# apollo4p register map
Vendor: Ambiq Micro; Series: Apollo; File version: 1.0
CPU: CM4 r1p0, little endian, MPU, FPU, I-cache, D-cache, VTOR, ITCM, DTCM, 3 interrupt priority bits, 0 interrupts
Registers are 32-bit, read-write, reset 0x0 unless marked. A register's access mark holds for its fields unless they carry their own. Offsets are from the block's base; [hi:lo] are bit positions; {n}, {i} and the like mark numbered series; 'fields as' and 'values as' point back to an identical list.

## MCUCTRL — MCU Miscellaneous Control Logic
Base 0x40020000
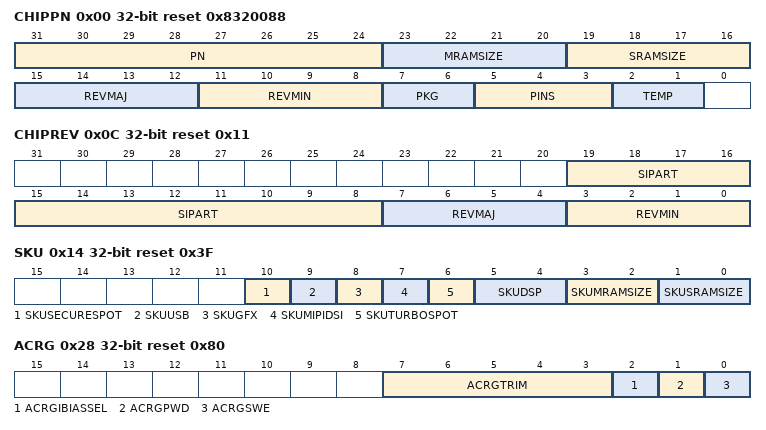
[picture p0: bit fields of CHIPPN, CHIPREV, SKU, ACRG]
0x00 CHIPPN reset 0x8320088 — Chip Information
  [31:24] PN — Apollo family device type.
    9=APOLLO4L (Apollo4L part number is 0x09xxxxxx.); 8=APOLLO4 (Apollo4 part number is 0x08xxxxxx.); 7=APOLLO3P (Apollo3P part number is 0x07xxxxxx.); 6=APOLLO3 (Apollo3 part number is 0x06xxxxxx.); 3=APOLLO2 (Apollo2 part number is 0x03xxxxxx.); 1=APOLLO (Apollo part number is 0x01xxxxxx.)
  [23:20] MRAMSIZE
    0=0P5MB (MRAM size is 0.5MB); 1=1P0MB (MRAM size is 1.0MB); 2=1P5MB (MRAM size is 1.5MB); 3=2P0MB (MRAM size is 2.0MB)
  [19:16] SRAMSIZE
    0=384_512 (SRAM size is 384KB+512KB); 1=384_1024 (SRAM size is 384KB+1MB); 2=384_1024_384_96 (SRAM size is 384KB+1MB+384KB+96KB)
  [15:12] REVMAJ — Major revision.
    0=A (Major Rev A); 1=B (Major Rev B); 2=C (Major Rev C)
  [11:8] REVMIN — Minor revision.
    0=Minor Rev 0; 1=Minor Rev 1
  [7:6] PKG — Package type.
    0=SIP (SIP package.); 1=SIP2 (SIP2 package.); 2=BGA (BGA package.); 3=CSP (CSP package.)
  [5:3] PINS — Number of pins for this package.
    0=25 pins; 1=49 pins; 2=64 pins; 3=81 pins
  [2:1] TEMP — Temperature.
    0=COM (Commercial temperature); 1=MIL (Military temperature); 2=AUTO (Automotive temperature); 3=IND (Industrial temperature)
0x04 CHIPID0 — Unique Chip ID 0
  [31:0] CHIPID0 — Unique chip ID 0.
0x08 CHIPID1 — Unique Chip ID 1
  [31:0] CHIPID1 — Unique chip ID 1.
0x0C CHIPREV reset 0x11 — Chip Revision
  [19:8] SIPART — Silicon Part ID
  [7:4] REVMAJ — Major Revision ID.
    3=C (Apollo4 revision C); 2=B (Apollo4 revision B); 1=A (Apollo4 revision A)
  [3:0] REVMIN — Minor Revision ID.
    3=REV2 (Apollo4 minor rev 2.); 2=REV1 (Apollo4 minor rev 1.); 1=REV0 (Apollo4 minor rev 0. Minor revision value, succeeding minor revisions will increment from this value.)
0x10 VENDORID — Unique Vendor ID
  [31:0] VENDORID
    0x414D4251=AMBIQ (Ambiq Vendor ID 'AMBQ'); 0=DEFAULT (Default Vendor ID)
0x14 SKU reset 0x3F — Unique Chip SKU
  [10] SKUSECURESPOT — Secure boot feature
  [9] SKUUSB — USB available
  [8] SKUGFX — GFX available
  [7] SKUMIPIDSI — MIPI DSI available
  [6] SKUTURBOSPOT — High performance mode for MCU and DSPs.
  [5:4] SKUDSP — DSP availability SKU setting. 384K available by default. Memory SU disabled
  [3:2] SKUMRAMSIZE — MRAM size SKU. All of 2MB Available by default. Memory SU disabled
  [1:0] SKUSRAMSIZE — SRAM SKU dictates the available memory for MCU. All of the MCU TCM (384KB) and System SRAM (2MB) available by default. Memory SU disabled
0x20 DEBUGGER — Debugger Control
  [31:0] LOCKOUT — Lockout of debugger (SWD).
0x28 ACRG reset 0x80 — Active Current Reference Generator Control
  [7:3] ACRGTRIM — ACRG Trim value
  [2] ACRGIBIASSEL — Set the ACRG ibias. Note: the SWE mux select in PWRSEQ2SWE must be set for this to take effect. The inversion of this register is driven to analog.
    0=BGSEL (Selects the bandgap); 1=CCRGSEL (Selects the CCRG)
  [1] ACRGPWD — Power down the ACRG.
    1=ACRG_PWR_DN (Powers down the ACRG trim.); 0=ACRG_PWR_UP (Power up the ACRG trim.)
  [0] ACRGSWE — Software enablement for ACRG register. A value of 1 will allow writes to the register
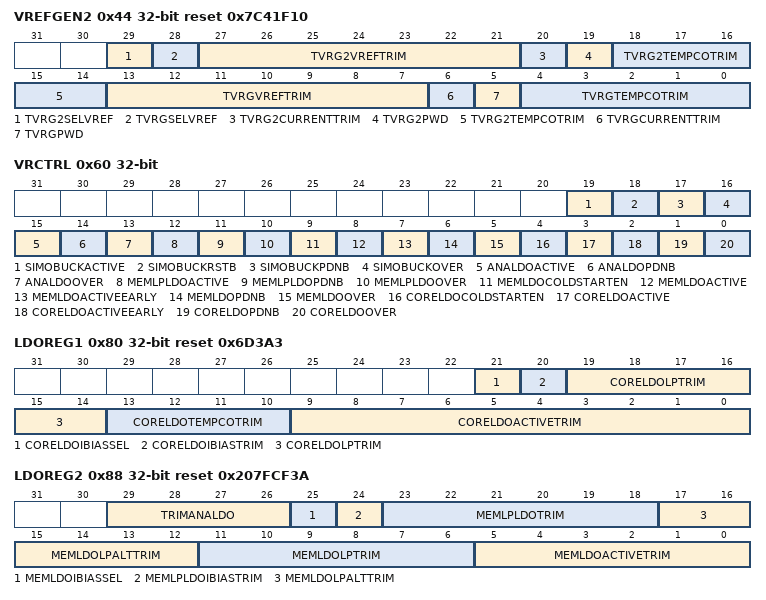
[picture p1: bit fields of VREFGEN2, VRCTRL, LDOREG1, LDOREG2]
0x44 VREFGEN2 reset 0x7C41F10 — Voltage Reference Generator 2 Control
  [29] TVRG2SELVREF
  [28] TVRGSELVREF
  [27:21] TVRG2VREFTRIM — Calibrated voltage reference 580m trim
  [20] TVRG2CURRENTTRIM — Calibrated voltage reference current trim.
  [19] TVRG2PWD — Power Down, Calibrated Voltage Reference Generator.
    1=PWR_DN (Powers down the CVRG.); 0=PWR_UP (Power up the CVRG.)
  [18:14] TVRG2TEMPCOTRIM — Calibrated Voltage Reference Generator tc trim (bottom transistor)
  [13:7] TVRGVREFTRIM — Calibrated voltage reference 580m trim
  [6] TVRGCURRENTTRIM — Calibrated voltage reference current trim.
  [5] TVRGPWD — Power Down, Calibrated Voltage Reference Generator.
    values as TVRG2PWD
  [4:0] TVRGTEMPCOTRIM — Calibrated Voltage Reference Generator tc trim (bottom transistor)
0x60 VRCTRL — Overrides for Voltage Regulators Controls
  [19] SIMOBUCKACTIVE — SIMO BUCK ACTIVE control. Override for PWRCTRL going to analog when SIMOBUCKOVER = 1
  [18] SIMOBUCKRSTB — SIMO BUCK RSTB control. Override for PWRCTRL going to analog when SIMOBUCKOVER = 1
  [17] SIMOBUCKPDNB — SIMO BUCK PDNB control. Override for PWRCTRL going to analog when SIMOBUCKOVER = 1
  [16] SIMOBUCKOVER — Override control for SIMO BUCK signals
  [15] ANALDOACTIVE — ANALDO LDO ACTIVE control. Override for PWRCTRL going to analog when ANALDOOVER = 1
  [14] ANALDOPDNB — ANALDO PDNB control. Override for PWRCTRL going to analog when ANALDOOVER = 1
  [13] ANALDOOVER — Override control for ANALDO signals
  [12] MEMLPLDOACTIVE — MEM LP LDO ACTVIVE control. Override for PWRCTRL going to analog when MEMLPLDOOVER = 1
  [11] MEMLPLDOPDNB — MEM LP LDO PDNB control. Override for PWRCTRL going to analog when MEMLPLDOOVER = 1
  [10] MEMLPLDOOVER — Override control for MEM LP LDO signals
  [9] MEMLDOCOLDSTARTEN — MEM LDO COLDSTART EN control. This is a shadow backed register and no need to set MEMLDOOVER.
  [8] MEMLDOACTIVE — MEM LDO ACTIVE control. Override for PWRCTRL going to analog when MEMLDOOVER = 1
  [7] MEMLDOACTIVEEARLY — MEM LDO EARLY ACTIVE control. Override for PWRCTRL going to analog when MEMLDOOVER = 1
  [6] MEMLDOPDNB — MEM LDO PDNB control. Override signal for PWRCTRL going to analog when MEMLDOOVER = 1
  [5] MEMLDOOVER — Override control for MEM LDO signals
  [4] CORELDOCOLDSTARTEN — CORE LDO COLDSTART EN control. This is a shadow backed register and no need to set CORELDOOVER.
  [3] CORELDOACTIVE — CORE LDO ACTIVE control. Override for PWRCTRL going to analog when CORELDOOVER = 1
  [2] CORELDOACTIVEEARLY — CORE LDO EARLY ACTIVE control. Override for PWRCTRL going to analog when CORELDOOVER = 1
  [1] CORELDOPDNB — CORE LDO PDNB control. Override for PWRCTRL going to analog when CORELDOOVER = 1
  [0] CORELDOOVER — Override control for CORE LDO signals
0x80 LDOREG1 reset 0x6D3A3 — CORELDO trims Reg
  [21] CORELDOIBIASSEL — Core LDO IBIAS sel. Note: the SWE mux select in PWRSEQ2SWE must be set for this to take effect.
  [20] CORELDOIBIASTRIM
  [19:14] CORELDOLPTRIM — CORE LDO Low Power Trim
  [13:10] CORELDOTEMPCOTRIM
  [9:0] CORELDOACTIVETRIM
0x88 LDOREG2 reset 0x207FCF3A — MEMLDO and MEMLPLDO Trims
  [29:26] TRIMANALDO — Analog LDO Trim.
  [25] MEMLDOIBIASSEL — Mem LDO IBIAS sel. Note: the SWE mux select in PWRSEQ2SWE must be set for this to take effect.
  [24] MEMLPLDOIBIASTRIM
  [23:18] MEMLPLDOTRIM
  [17:12] MEMLDOLPALTTRIM — MEM LDO TRIM LP ALT SET
  [11:6] MEMLDOLPTRIM
  [5:0] MEMLDOACTIVETRIM
0xC4 HFRC2 — HFRC2 Control
  [21:11] HF2TUNE — Default HFRC2 frequency tune value
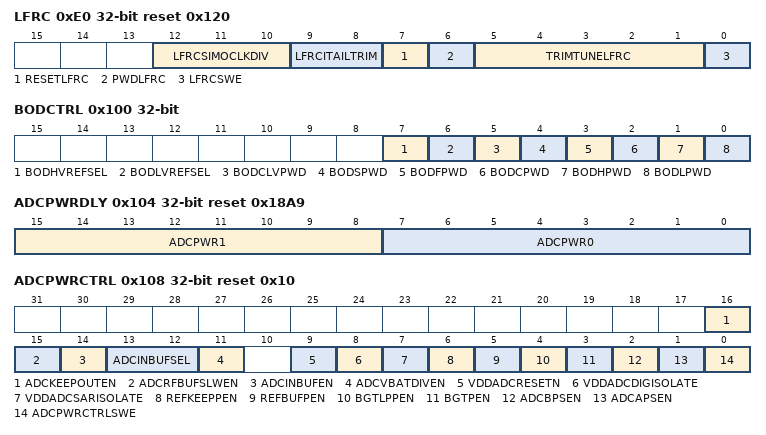
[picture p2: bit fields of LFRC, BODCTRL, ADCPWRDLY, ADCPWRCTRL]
0xE0 LFRC reset 0x120 — LFRC Control
  [12:10] LFRCSIMOCLKDIV — SIMOBUCK LP mode clock divider
    0=DIV1 (Divide by 1); 1=DIV2 (Divide by 2); 2=DIV4 (Divide by 4); 3=DIV8 (Divide by 8); 4=DIV16 (Divide by 16); 5=DIV32 (Divide by 32)
  [9:8] LFRCITAILTRIM
  [7] RESETLFRC — LFRC Reset.
    0=EN (Enable LFRC.); 1=RESET (Reset LFRC.)
  [6] PWDLFRC — Power Down LFRC.
    0=PWRUP (Power up LFRC.); 1=PWRDN (Power down LFRC.)
  [5:1] TRIMTUNELFRC — LFRC Frequency Tune trim bits
  [0] LFRCSWE — LFRC Software Override Enable.
    0=OVERRIDE_DIS (LFRC Software Override Disable.); 1=OVERRIDE_EN (LFRC Software Override Enable.)
0x100 BODCTRL — BOD control
  [7] BODHVREFSEL — BODH External Reference Select. Note: the SWE mux select in PWRSEQ2SWE must be set for this to take effect.
  [6] BODLVREFSEL — BODL External Reference Select. Note: the SWE mux select in PWRSEQ2SWE must be set for this to take effect.
  [5] BODCLVPWD — BODC_LV Power Down.
  [4] BODSPWD — BODS Power Down.
  [3] BODFPWD — BODF Power Down.
  [2] BODCPWD — BODC Power Down.
  [1] BODHPWD — BODH Power Down.
  [0] BODLPWD — BODL Power Down.
0x104 ADCPWRDLY reset 0x18A9 — ADC Power Up Delay Control
  [15:8] ADCPWR1 — Delay time for ADC Reference Buffer settling time in 64x ADC clock increments. Delay = 64*ADCPWR1*ADC_CLK
  [7:0] ADCPWR0 — Additional delay time for ADC Reference Buffer settling time in 64x ADC clock increments. Delay = 64*ADCPWR0*ADC_CLK.
0x108 ADCPWRCTRL reset 0x10 — ADC Power Control
  [16] ADCKEEPOUTEN — ADC reference keeper out en
  [15] ADCRFBUFSLWEN — ADC reference buffer slew enable
  [14] ADCINBUFEN — ADC Input Buffer Power Enable ( if the ADCPWRCTRLSWE bit is set )
  [13:12] ADCINBUFSEL — ADC input buffer mux select
  [11] ADCVBATDIVEN — ADC VBAT DIV Power Enable ( if the ADCPWRCTRLSWE bit is set )
  [9] VDDADCRESETN — RESETN signal for Power Switched SAR and Digital Controller (when global power switch is off and if the ADCPWRCTRLSWE bit is set)
    0=ASSERT (Resetn is asserted); 1=DEASSERT (Resetn is de-asserted)
  [8] VDDADCDIGISOLATE — ISOLATE signal for ADC Digital Contoller ( when ADCAPSEN is switched off and if the ADCPWRCTRLSWE bit is set)
    0=DIS (No Isolation); 1=EN (Isolate)
  [7] VDDADCSARISOLATE — ISOLATE signal for Power Switched SAR ( when ADCBPSEN is switched off )
    0=DIS (No Isolation); 1=EN (Isolate)
  [6] REFKEEPPEN — Reference Buffer Keeper Power Switch Enable
    0=DIS (Reference Buffer Keeper Power Switch disable.); 1=EN (Reference Buffer Keeper Power Switch enable.)
  [5] REFBUFPEN — Reference Buffer Power Switch Enable
    0=DIS (Reference Buffer Power Switch disable.); 1=EN (Reference Buffer Power Switch enable.)
  [4] BGTLPPEN — Bandgap and Temperature Sensor Power Switch Enable
    0=DIS (Bandgap and temperature sensor disable.); 1=EN (Bandgap and temperature sensor enable.)
  [3] BGTPEN — Bandgap and Temperature Sensor Power Switch Enable
    values as BGTLPPEN
  [2] ADCBPSEN — Enable the Analog, IO and SAR Digital logic Power Switch on when set to 1 if the ADCPWRCTRLSWE bit is set.
    0=DIS (ADC power switch software power disable.); 1=EN (ADC power switch software power enable.)
  [1] ADCAPSEN — Enable the Global ADC Power Switch on when set to 1 if the ADCPWRCTRLSWE bit is set.
    values as ADCBPSEN
  [0] ADCPWRCTRLSWE — ADC Power Control Software Override Enable
    0=OVERRIDE_DIS (ADC temperature sensor and bandgap Software Override Disable.); 1=OVERRIDE_EN (ADC temperature sensor and bandgap Software Override Enable.)
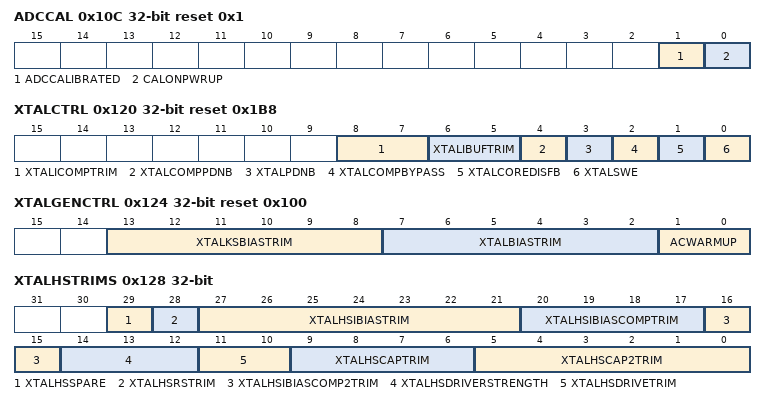
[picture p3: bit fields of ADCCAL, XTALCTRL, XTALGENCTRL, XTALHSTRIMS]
0x10C ADCCAL reset 0x1 — ADC Calibration Control
  [1] ADCCALIBRATED — Status for ADC Calibration
    0=FALSE (ADC is not calibrated); 1=TRUE (ADC is calibrated)
  [0] CALONPWRUP — Run ADC Calibration on initial power up sequence
    0=DIS (Disable automatic calibration on initial power up); 1=EN (Enable automatic calibration on initial power up)
0x110 ADCBATTLOAD — ADC Battery Load Enable
  [0] BATTLOAD — Enable the ADC battery load resistor
    0=DIS (Battery load is disconnected); 1=EN (Battery load is enabled)
0x120 XTALCTRL reset 0x1B8 — XTAL Oscillator Control
  [8:7] XTALICOMPTRIM
  [6:5] XTALIBUFTRIM — XTAL IBUFF trim
  [4] XTALCOMPPDNB — XTAL Oscillator Power Down Comparator.
    1=PWRUPCOMP (Power up XTAL oscillator comparator.); 0=PWRDNCOMP (Power down XTAL oscillator comparator.)
  [3] XTALPDNB — XTAL Oscillator Power Down Core.
    1=PWRUPCORE (Power up XTAL oscillator core.); 0=PWRDNCORE (Power down XTAL oscillator core.)
  [2] XTALCOMPBYPASS — XTAL Oscillator Bypass Comparator.
    0=USECOMP (Use the XTAL oscillator comparator.); 1=BYPCOMP (Bypass the XTAL oscillator comparator.)
  [1] XTALCOREDISFB — XTAL Oscillator Disable Feedback.
    0=EN (Enable XTAL oscillator comparator.); 1=DIS (Disable XTAL oscillator comparator.)
  [0] XTALSWE — XTAL Software Override Enable.
    0=OVERRIDE_DIS (XTAL Software Override Disable.); 1=OVERRIDE_EN (XTAL Software Override Enable.)
0x124 XTALGENCTRL reset 0x100 — XTAL Oscillator General Control
  [13:8] XTALKSBIASTRIM — XTAL IBIAS Kick start trim. This trim value is used during the startup process to enable a faster lock.
  [7:2] XTALBIASTRIM
  [1:0] ACWARMUP — Auto-calibration delay control
    0=SEC1 (Warmup period of 1-2 seconds); 1=SEC2 (Warmup period of 2-4 seconds); 2=SEC4 (Warmup period of 4-8 seconds); 3=SEC8 (Warmup period of 8-16 seconds)
0x128 XTALHSTRIMS
  [29] XTALHSSPARE, [28] XTALHSRSTRIM, [27:21] XTALHSIBIASTRIM, [20:17] XTALHSIBIASCOMPTRIM, [16:15] XTALHSIBIASCOMP2TRIM, [14:12] XTALHSDRIVERSTRENGTH, [11:10] XTALHSDRIVETRIM, [9:6] XTALHSCAPTRIM, [5:0] XTALHSCAP2TRIM
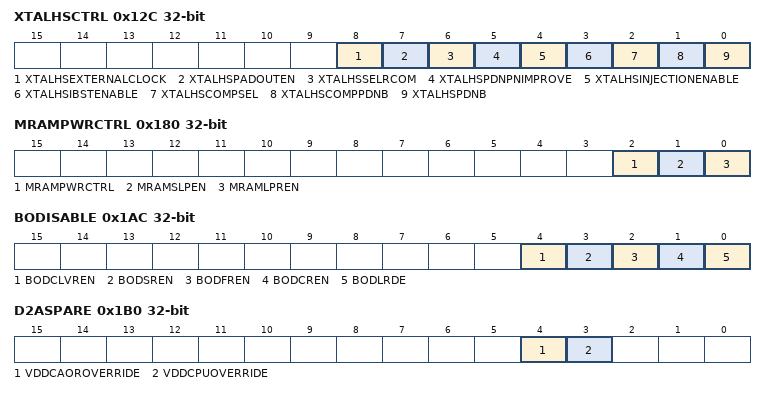
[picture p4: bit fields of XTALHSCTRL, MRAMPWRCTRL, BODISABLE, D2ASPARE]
0x12C XTALHSCTRL — XTALHS Control
  [8] XTALHSEXTERNALCLOCK, [7] XTALHSPADOUTEN, [6] XTALHSSELRCOM, [5] XTALHSPDNPNIMPROVE, [4] XTALHSINJECTIONENABLE, [3] XTALHSIBSTENABLE, [2] XTALHSCOMPSEL, [1] XTALHSCOMPPDNB, [0] XTALHSPDNB
0x180 MRAMPWRCTRL — MRAM Power Control
  [2] MRAMPWRCTRL — MRAM low power mode control. When set to 1, tmc_lpr and tmc_slp are driven by the value of MRAMLPREN and MRAMSLPEN of this register.
  [1] MRAMSLPEN — MRAM sleep mode enable
  [0] MRAMLPREN — MRAM low power mode enable
0x1AC BODISABLE — Brownout Disable
  [4] BODCLVREN — Disable VDDC_LV Brown Out reset.
    1=EN (Enable VDDC_LV Brown Out reset.); 0=DIS (Disable VDDC_LV Brown Out reset.)
  [3] BODSREN — Disable VDDS Brown Out reset.
    1=EN (Enable VDDS Brown Out reset.); 0=DIS (Disable VDDS Brown Out reset.)
  [2] BODFREN — Disable VDDF Brown Out reset.
    1=EN (Enable VDDF Brown Out reset.); 0=DIS (Disable VDDF Brown Out reset.)
  [1] BODCREN — Disable VDDC Brown Out reset.
    1=EN (Enable VDDC Brown Out reset.); 0=DIS (Disable VDDC Brown Out reset.)
  [0] BODLRDE — Disable Unregulated 1.8V Brown-out reset.
    0=EN (Enable Unregulated 1.8v brown out reset.); 1=DIS (Disable Unregulated 1.8v brown out reset.)
0x1B0 D2ASPARE — Spare registers to analog module
  [4] VDDCAOROVERRIDE — VDDCAOR Override. Set to 1 to connect to the VDDC rail, set to 0 to connect to the VDDC_LV rail. Before setting this bit to 0, the VDDC_LV rail must first be enabled by setting SIMOBUCK0_b.VDDCLVRXCOMPEN. Do not modify this field unless directed to do so by Ambiq engineering. If modifying, a RMW operation such as MCUCTRL->D2ASPARE_b.VDDCAOROVERRIDE=1 must be used.
  [3] VDDCPUOVERRIDE — VDDCPU Override. Set to 1 to connect to the VDDC rail, set to 0 to connect to the VDDC_LV rail. Before setting this bit to 0, the VDDC_LV rail must first be enabled by setting SIMOBUCK0_b.VDDCLVRXCOMPEN. Do not modify this field unless directed to do so by Ambiq engineering. If modifying, a RMW operation such as MCUCTRL->D2ASPARE_b.VDDCPUOVERRIDE=1 must be used.
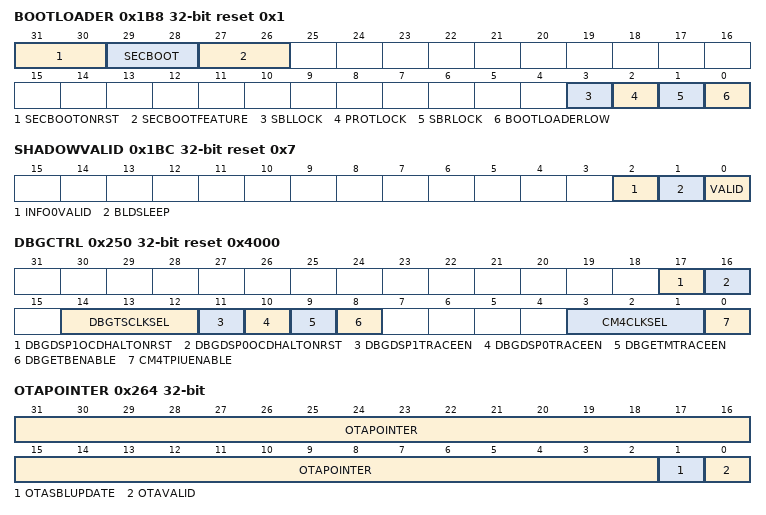
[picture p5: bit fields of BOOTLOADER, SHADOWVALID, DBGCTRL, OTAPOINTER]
0x1B8 BOOTLOADER reset 0x1 — Bootloader and secure boot functions
  [31:30] SECBOOTONRST — Indicates whether the secure boot on warm reset is enabled
    0=DISABLED (Secure boot disabled); 1=ENABLED (Secure boot enabled); 2=ERROR (Error in secure boot configuration)
  [29:28] SECBOOT — Indicates whether the secure boot on cold reset is enabled
    values as SECBOOTONRST
  [27:26] SECBOOTFEATURE — Indicates whether the secure boot feature is enabled.
    values as SECBOOTONRST
  [3] SBLLOCK — Secure boot loader lock. Always resets to 1, write 1 to clear. Enables system visibility to bootloader until set.
    1=LOCK (Enable the secure boot lock); 0=UNLOCK (Disable the secure boot lock)
  [2] PROTLOCK — This field controls access to OEM keybank and restricts further application of NVM protections via the FLASHWPROTn and FLASHRPROTn registers. On read, 0 indicates locked, 1 indicates unlocked. Write 1 to clear the field (assert the lock). Default value of the hardware is 1 (unlocked), but the default value is also affected by INFOC_SECURITY->PLONEXIT. If PLONEXIT is set, PROTLOCK is asserted by SBL and the OEM application will see the value as 0 (locked).
    1=LOCK (On write, this value asserts the lock. On read, see above description.); 0=DEFAULT (On write, this value (writing 0) has no effect. On read, see above description.)
  [1] SBRLOCK — Secure boot ROM lock. Always resets to 1, write 1 to clear. Enables system visibility to bootloader until set.
    1=LOCK (Enable the secure boot lock); 0=DEFAULT (Default value.)
  [0] BOOTLOADERLOW — Determines whether the bootloader code is visible at address 0x00000000 or not. Resets to 1, write 1 to clear.
    1=ADDR0 (Bootloader code at 0x00000000.); 0=NOADDR0 (Bootloader code is not visible at address)
0x1BC SHADOWVALID reset 0x7 — Register to indicate whether the shadow registers have been successfully loaded from the Flash Information Space.
  [2] INFO0VALID — Indicates whether info0 contains valid data
    1=VALID (Flash info0 (customer) space contains valid data.); 0=DEFAULT (Default value.)
  [1] BLDSLEEP — Indicates whether the bootloader should sleep or deep sleep if no image loaded.
    1=DEEPSLEEP (Bootloader will go to deep sleep if no flash image loaded); 0=SLEEP (Bootloader will go to normalsleep if no flash image loaded)
  [0] VALID — Indicates whether the shadow registers contain valid data from the Flash Information Space.
    1=VALID (Flash information space contains valid data.); 0=DEFAULT (Default value.)
0x1C0 SCRATCH0 — Scratch register that is not reset by any reset
  [31:0] SCRATCH0 — Scratch register 0.
0x1C4 SCRATCH1 — Scratch register that is not reset by any reset
  [31:0] SCRATCH1 — Scratch register 1.
0x200 DBGR1 reset 0x12345678 — Read-only debug 1
  [31:0] ONETO8 — Read-only register for communication validation
0x204 DBGR2 reset 0xC001C0DE — Read-only debug 2
  [31:0] COOLCODE — Read-only register for communication validation
0x220 PMUENABLE reset 0x1 — Control bit to enable/disable the PMU
  [0] ENABLE — PMU Enable Control bit. When set, the MCU's PMU will place the MCU into the lowest power consuming Deep Sleep mode upon execution of a WFI instruction (dependent on the setting of the SLEEPDEEP bit in the ARM SCR register). When cleared, regardless of the requested sleep mode, the PMU will not enter the lowest power Deep Sleep mode, instead entering the Sleep mode.
    0=DIS (Disable MCU power management.); 1=EN (Enable MCU power management.)
0x250 DBGCTRL reset 0x4000 — Debug subsystem Control. Determines the debug components enable and clk frequency.
  [17] DBGDSP1OCDHALTONRST — Debug subsystem DSP1 OCD Halt on Reset
    0=DIS (Disable DSP1 OCD Halt on Reset.); 1=EN (Enable DSP1 OCD Halt on Reset.)
  [16] DBGDSP0OCDHALTONRST — Debug subsystem DSP0 OCD Halt on Reset
    0=DIS (Disable DSP0 OCD Halt on Reset.); 1=EN (Enable DSP0 OCD Halt on Reset.)
  [14:12] DBGTSCLKSEL — This field selects the frequency of the ARM M4 dbg ts port.
    0=LOWPWR (Low power state.); 1=HFRCDIV2 (Selects HFRC divided by 2 as the source dbg ts clk); 2=HFRCDIV8 (Selects HFRC divided by 8 as the source dbg ts clk); 3=HFRCDIV16 (Selects HFRC divided by 16 as the source dbg ts clk); 4=HFRCDIV32 (Selects HFRC divided by 32 as the source dbg ts clk)
  [11] DBGDSP1TRACEEN — Debug subsystem DSP1 trace enable
    0=DIS (Disable DSP1 trace.); 1=EN (Enable DSP1 trace.)
  [10] DBGDSP0TRACEEN — Debug subsystem DSP0 trace enable
    0=DIS (Disable DSP0 trace.); 1=EN (Enable DSP0 trace.)
  [9] DBGETMTRACEEN — Debug subsystem ETM trace enable
    0=DIS (Disable ETM trace.); 1=EN (Enable ETM trace.)
  [8] DBGETBENABLE — Debug subsystem ETB enable to store the trace data.
    0=DIS (Disable ETB.); 1=EN (Enable ETB.)
  [3:1] CM4CLKSEL — This field selects the frequency of the ARM M4 TPIU port.
    0=LOWPWR (Low power state.); 1=HFRC96 (Selects HFRC 96Mhz as the source TPIU clk); 2=HFRC48 (Selects HFRC 48Mhz as the source TPIU clk); 3=HFRC24 (Selects HFRC 24Mhz as the source TPIU clk); 4=HFRC6 (Selects HFRC 6Mhz as the source TPIU clk); 5=HFRC3 (Selects HFRC 3Mhz as the source TPIU clk); 6=HFRC1P5 (Selects HFRC 1.5Mhz as the source TPIU clk); 7=HFRC2_192 (Selects HFRC2 192Mhz as the source TPIU clk. Note that this setting requires CLKGEN.MISC.HFRC2 be enabled.)
  [0] CM4TPIUENABLE — TPIU Enable field. When set, the ARM M4 TPIU is enabled and data can be streamed out trace data from ARM ITM and ETM modules through either SWO or TRACEDATA ports
    0=DIS (Disable the TPIU.); 1=EN (Enable the TPIU.)
0x264 OTAPOINTER — OTA (Over the Air) Update Pointer/Status. Reset only by POA
  [31:2] OTAPOINTER — Flash page pointer with updated OTA image
  [1] OTASBLUPDATE — Indicates that the sbl_init has been updated
  [0] OTAVALID — Indicates that an OTA update is valid
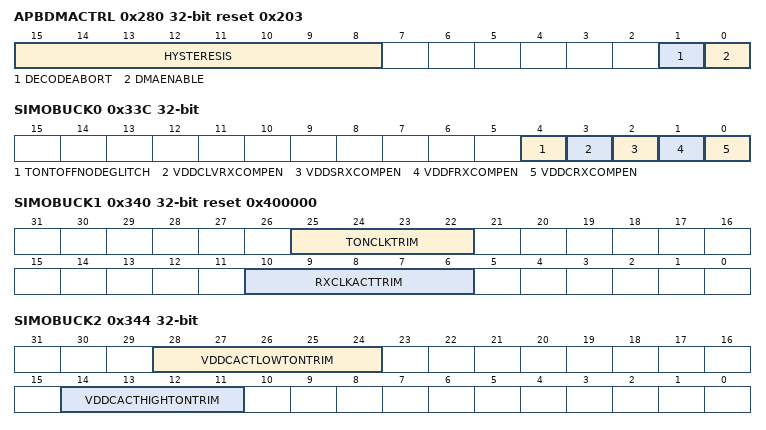
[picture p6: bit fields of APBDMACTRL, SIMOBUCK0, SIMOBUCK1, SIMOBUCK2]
0x280 APBDMACTRL reset 0x203 — DMA Control Register. Determines misc settings for DMA operation
  [15:8] HYSTERESIS — This field determines how long the DMA engine of apb/disp/gfx will remain active during deep sleep before shutting down and returning the system to full deep sleep. Values are based on a 94KHz clock and are roughly 10us increments for a range of ~10us to 2.55ms
  [1] DECODEABORT — APB Decode Abort. When set, the APB bridge will issue a data abort (bus fault) on transactions to peripherals that are powered down. When set to 0, writes are quietly discarded and reads return 0.
    0=DISABLE (Bus operations to powered down peripherals are quietly discarded); 1=ENABLE (Bus operations to powered down peripherals result in a bus fault.)
  [0] DMAENABLE — Enable the DMA controller. When disabled, DMA requests will be ignored by the controller
    0=DISABLE (DMA operations disabled); 1=ENABLE (DMA operations enabled)
0x338 KEXTCLKSEL — Locks the state of the EXTCLKSEL register from writes. This is done to prevent errant writes to the register, as this could cause the chip to halt. Write a value of 0x53 to unlock write access to the EXTCLKSEL register. Once unlocked, the register will read back a 1 to undicate this is unlocked. Writing the register with any other value other than 0x53 will enable the lock.
  [31:0] KEXTCLKSEL — Key register value.
    83=Key (Key value to unlock the register.)
0x33C SIMOBUCK0 — This WRITE_ONLY register controls various buck parameters. It will read back as 0x00000000.
  [4] TONTOFFNODEGLITCH — Enable the ton and toff signals no deglitch output.
  [3] VDDCLVRXCOMPEN — Enable the VDDC LV rail.
  [2] VDDSRXCOMPEN — Enable the VDDS rail.
  [1] VDDFRXCOMPEN — Enable the VDDS rail.
  [0] VDDCRXCOMPEN — Enable the VDDC rail.
0x340 SIMOBUCK1 reset 0x400000 — 1. Control the even division of 3 clocks: refresh, low power and TONCLK. 2. Control gap bewteen secondary switches. 3. Debug features: control the amount of time TONCLK is on, and the time before snubber asserts for each buck sequence. 4. Enable or disable the observation bus. 5. Select the buck sequence operation mode. 6. Control delay between primary Pmos and Nmos transitions.
  [25:22] TONCLKTRIM — This divides the 100 MHz ton clock. Even divides are supported only. This value represents the division amount minus 1.
  [10:6] RXCLKACTTRIM — This divides the 5 MHz refresh clock. Even divides are supported only. This value represents the division amount minus 1.
0x344 SIMOBUCK2 — SIMO Buck Muxed VDDC Active Sequence Trim Control
  [28:24] VDDCACTLOWTONTRIM — VDDC active high ton trim control for Buck sequence.
  [14:11] VDDCACTHIGHTONTRIM — VDDC active high ton trim control for Buck sequence.
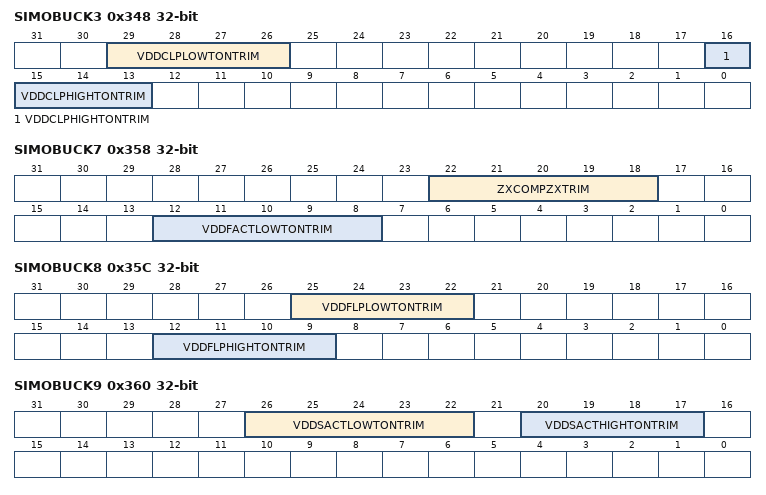
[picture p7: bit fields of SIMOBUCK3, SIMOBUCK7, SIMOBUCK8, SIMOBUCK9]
0x348 SIMOBUCK3 — SIMO Buck Muxed VDDC low power Sequence Trim Control
  [29:26] VDDCLPLOWTONTRIM — VDDC LP low ton trim control for Buck sequence.
  [16:13] VDDCLPHIGHTONTRIM — VDDC LP high ton trim control for Buck sequence.
0x354 SIMOBUCK6 — SIMO Buck Muxed VDDF Active Sequence Trim Control
  [20:17] VDDFACTHIGHTONTRIM — VDDF active high ton trim control for Buck sequence.
0x358 SIMOBUCK7 — SIMO Buck Muxed VDDF active Sequence Trim Control
  [22:18] ZXCOMPZXTRIM — Zxcomp trim. Feedthrough to analog.
  [12:8] VDDFACTLOWTONTRIM — VDDF active low ton trim control for Buck sequence.
0x35C SIMOBUCK8 — SIMO Buck Muxed VDDF Low Power Sequence Trim Control
  [25:22] VDDFLPLOWTONTRIM — VDDF low power low ton trim control for Buck sequence.
  [12:9] VDDFLPHIGHTONTRIM — VDDF low power high ton trim control for Buck sequence.
0x360 SIMOBUCK9 — SIMO Buck Muxed VDDS Active Sequence Trim Control
  [26:22] VDDSACTLOWTONTRIM — VDDS active low ton trim control for Buck sequence.
  [20:17] VDDSACTHIGHTONTRIM — VDDS active high ton trim control for Buck sequence.
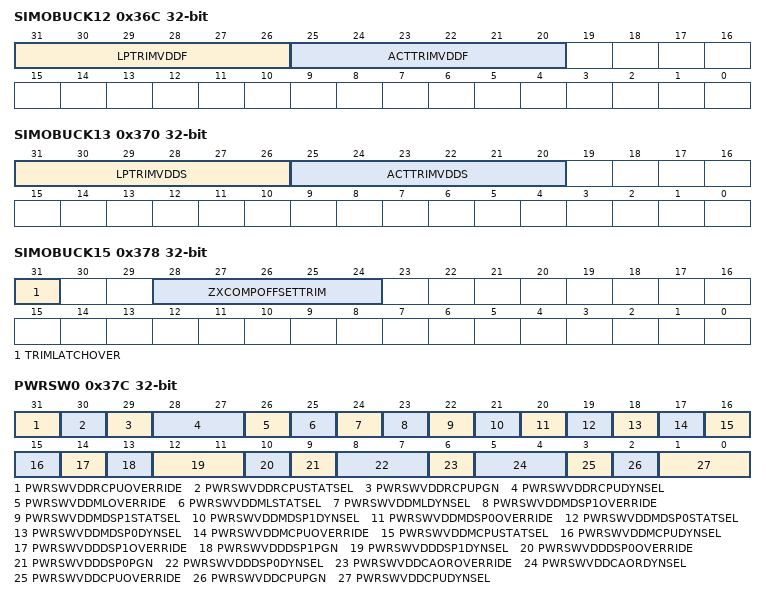
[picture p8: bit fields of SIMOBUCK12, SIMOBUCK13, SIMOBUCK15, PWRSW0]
0x36C SIMOBUCK12 — SIMO Buck Compare, Brown out, Active, Low power Trim Control
  [31:26] LPTRIMVDDF — Low power VDDF trim.
  [25:20] ACTTRIMVDDF — Active VDDF trim.
0x370 SIMOBUCK13 — SIMO Buck Compare, Brown out, Active, Low power Trim Control
  [31:26] LPTRIMVDDS — Low power VDDS trim.
  [25:20] ACTTRIMVDDS — Active VDDS trim.
0x378 SIMOBUCK15 — SIMO Buck Compare, Brown out, Active and Low power Trim Control
  [31] TRIMLATCHOVER — Override / Bypass the simobuck trim latch to enable on-the-fly trimming for VDDF and VDDS active and LP trims
  [28:24] ZXCOMPOFFSETTRIM — Zxcomp offset trim. Feedthrough to analog.
0x37C PWRSW0 — PWRSW Control 0
  [31] PWRSWVDDRCPUOVERRIDE — override enable for pwrsw_vddrcpu_dynsel and pgn
  [30] PWRSWVDDRCPUSTATSEL — VDDRCPU power switch static select
    1=VDDC (Select VDDC rail); 0=VDDFLP (Select VDDFLP rail)
  [29] PWRSWVDDRCPUPGN — override value for pwrsw_vddrcpu_pgn
  [28:27] PWRSWVDDRCPUDYNSEL — override value for pwrsw_vddrcpu_dynsel
  [26] PWRSWVDDMLOVERRIDE — override enable for pwrsw_vddml_dynsel
  [25] PWRSWVDDMLSTATSEL — VDDML power switch static select
    0=VDDC (Select VDDC rail); 1=VDDF (Select VDDF rail)
  [24] PWRSWVDDMLDYNSEL — override value for pwrsw_vddml_dynsel
  [23] PWRSWVDDMDSP1OVERRIDE — override enable for pwrsw_vddmdsp1_dynsel
  [22] PWRSWVDDMDSP1STATSEL — VDDMDSP1 power switch static select
    0=VDDC (Select VDDC rail); 1=VDDF (Select VDDF rail)
  [21] PWRSWVDDMDSP1DYNSEL — override value for pwrsw_vddmdsp1_dynsel
  [20] PWRSWVDDMDSP0OVERRIDE — override enable for pwrsw_vddmdsp0_dynsel
  [19] PWRSWVDDMDSP0STATSEL — VDDMDSP0 power switch static select
    0=VDDC (Select VDDC rail); 1=VDDF (Select VDDF rail)
  [18] PWRSWVDDMDSP0DYNSEL — override value for pwrsw_vddmdsp0_dynsel
  [17] PWRSWVDDMCPUOVERRIDE — override enable for pwrsw_vddmcpu_dynsel
  [16] PWRSWVDDMCPUSTATSEL — VDDMCPU power switch static select
    0=VDDC (Select VDDC rail); 1=VDDF (Select VDDF rail)
  [15] PWRSWVDDMCPUDYNSEL — override value for pwrsw_vddmcpu_dynsel
  [14] PWRSWVDDDSP1OVERRIDE — override enable for pwrsw_vdddsp1_dynsel and pgn
  [13] PWRSWVDDDSP1PGN — override value for pwrsw_vdddsp1_pgn
  [12:11] PWRSWVDDDSP1DYNSEL — override value for pwrsw_vdddsp1_dynsel
  [10] PWRSWVDDDSP0OVERRIDE — override enable for pwrsw_vdddsp0_dynsel and pgn
  [9] PWRSWVDDDSP0PGN — override value for pwrsw_vdddsp0_pgn
  [8:7] PWRSWVDDDSP0DYNSEL — override value for pwrsw_vdddsp0_dynsel
  [6] PWRSWVDDCAOROVERRIDE — override enable for pwrsw_vddcaor_dynsel
  [5:4] PWRSWVDDCAORDYNSEL — override value for pwrsw_vddcaor_dynsel
  [3] PWRSWVDDCPUOVERRIDE — override enable for pwrsw_vddcpu_dynsel and pgn
  [2] PWRSWVDDCPUPGN — override value for pwrsw_vddcpu_pgn
  [1:0] PWRSWVDDCPUDYNSEL — override value for pwrsw_vddcpu_dynsel
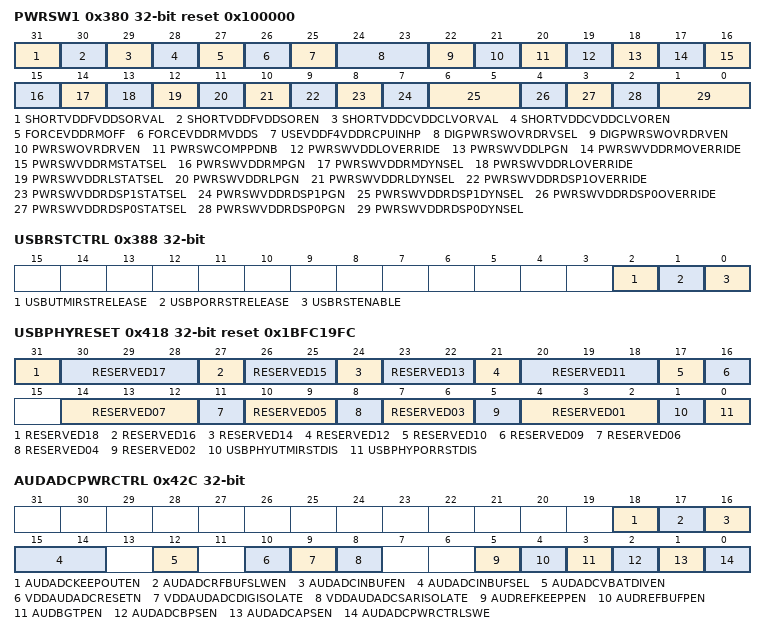
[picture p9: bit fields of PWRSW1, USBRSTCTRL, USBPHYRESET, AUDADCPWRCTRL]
0x380 PWRSW1 reset 0x100000 — PWRSW Control 1
  [31] SHORTVDDFVDDSORVAL — pwrsw short override value for vddf/vdds
  [30] SHORTVDDFVDDSOREN — pwrsw short override select for vddf/vdds
  [29] SHORTVDDCVDDCLVORVAL — pwrsw short override value for vddc/vddclv
  [28] SHORTVDDCVDDCLVOREN — pwrsw short override select for vddc/vddclv
  [27] FORCEVDDRMOFF — Setting this bit forces VDDRM to be open when Flash is off. This is valid for only normal operational mode (i.e. without overrides).
  [26] FORCEVDDRMVDDS — Setting this bit selects VDDS for VDDRM when Flash is off. This is valid for only normal operational mode (i.e. without overrides).
  [25] USEVDDF4VDDRCPUINHP — Setting this bit selects VDDF for VDDRCPU in when MCU is in HP mode. This is valid for only normal operational mode (i.e without overrides).
  [24:23] DIGPWRSWOVRDRVSEL
  [22] DIGPWRSWOVRDRVEN
  [21] PWRSWOVRDRVEN
  [20] PWRSWCOMPPDNB
  [19] PWRSWVDDLOVERRIDE — override enable for pwrsw_vddl_pgn
  [18] PWRSWVDDLPGN — override value for pwrsw_vddl_pgn
  [17] PWRSWVDDRMOVERRIDE — override enable for pwrsw_vddrm_dynsel and pgn
  [16] PWRSWVDDRMSTATSEL — VDDRM power switch static select
    1=VDDC (Select VDDC rail); 0=VDDFLP (Select VDDFLP rail)
  [15] PWRSWVDDRMPGN — override value for pwrsw_vddrm_pgn
  [14] PWRSWVDDRMDYNSEL — override value for pwrsw_vddrm_dynsel
  [13] PWRSWVDDRLOVERRIDE — override enable for pwrsw_vddrl_dynsel and pgn
  [12] PWRSWVDDRLSTATSEL — VDDRL power switch static select
    1=VDDC (Select VDDC rail); 0=VDDFLP (Select VDDFLP rail)
  [11] PWRSWVDDRLPGN — override value for pwrsw_vddrl_pgn
  [10] PWRSWVDDRLDYNSEL — override value for pwrsw_vddrl_dynsel
  [9] PWRSWVDDRDSP1OVERRIDE — override enable for pwrsw_vddrdsp1_dynsel and pgn
  [8] PWRSWVDDRDSP1STATSEL — VDDRDSP1 power switch static select
    1=VDDC (Select VDDC rail); 0=VDDFLP (Select VDDFLP rail)
  [7] PWRSWVDDRDSP1PGN — override value for pwrsw_vddrdsp1_pgn
  [6:5] PWRSWVDDRDSP1DYNSEL — override value for pwrsw_vddrdsp1_dynsel
  [4] PWRSWVDDRDSP0OVERRIDE — override enable for pwrsw_vddrdsp0_dynsel and pgn
  [3] PWRSWVDDRDSP0STATSEL — VDDRDSP0 power switch static select
    1=VDDC (Select VDDC rail); 0=VDDFLP (Select VDDFLP rail)
  [2] PWRSWVDDRDSP0PGN — override value for pwrsw_vddrdsp0_pgn
  [1:0] PWRSWVDDRDSP0DYNSEL — override value for pwrsw_vddrdsp0_dynsel
0x388 USBRSTCTRL — USB Reset Startup Control
  [2] USBUTMIRSTRELEASE — Set this bit to '1' after USB power domain is up. This will release the reset override condition
  [1] USBPORRSTRELEASE — Set this bit to '1' after USB power domain is up. This will release the reset override condition
  [0] USBRSTENABLE — This bit enables this register control. If set to '1', the reset release bits will be active. If set to '0', this register is not controlling the USB override bits.
{0x3A8+4i} FLASHWPROT{i} (i=0..3) — These bits write-protect flash in 16KB chunks.
  [31:0] FW{i}BITS — Write protect flash {0x0+0x80000*i} - {0x7FFFF+0x80000*i}. Each bit provides write protection for 16KB chunks of flash data space. Bits are cleared by writing a 1 to the bit. When read, 0 indicates the region is protected. Bits are sticky (can be set when PROTLOCK is 1, but only cleared by reset)
{0x3B8+4i} FLASHRPROT{i} (i=0..3) — These bits read-protect flash in 16KB chunks.
  [31:0] FR{i}BITS — Copy (read) protect flash {0x0+0x80000*i} - {0x7FFFF+0x80000*i}. Each bit provides read protection for 16KB chunks of flash. Bits are cleared by writing a 1 to the bit. When read, 0 indicates the region is protected. Bits are sticky (can be set when PROTLOCK is 1, but only cleared by reset)
0x3C8 DMASRAMWPROT0 — These bits write-protect system SRAM from DMA operations in 8KB chunks.
  [31:0] DMAWPROT0 — Write protect SRAM from DMA. Each bit provides write protection for an 8KB region of memory. When set to 1, the region will be protected from DMA writes, when set to 0, DMA may write the region.
0x3CC DMASRAMWPROT1 — These bits write-protect system SRAM from DMA operations in 8KB chunks.
  [15:0] DMAWPROT1 — Write protect SRAM from DMA. Each bit provides write protection for an 8KB region of memory. When set to 1, the region will be protected from DMA writes, when set to 0, DMA may write the region.
0x3D0 DMASRAMRPROT0 — These bits read-protect system SRAM from DMA operations in 8KB chunks.
  [31:0] DMARPROT0 — Read protect SRAM from DMA. Each bit provides write protection for an 8KB region of memory. When set to 1, the region will be protected from DMA reads, when set to 0, DMA may read the region.
0x3D4 DMASRAMRPROT1 — These bits read-protect system SRAM from DMA operations in 8KB chunks.
  [15:0] DMARPROT1 — Read protect SRAM from DMA. Each bit provides write protection for an 8KB region of memory. When set to 1, the region will be protected from DMA reads, when set to 0, DMA may read the region.
0x418 USBPHYRESET reset 0x1BFC19FC — DSP0 CACHE RAM TRIM
  [31] RESERVED18 — Self-timed override (test mode only)
  [30:28] RESERVED17 — DSP0 ICACHE DATA WABLM - 00=No adjust 11=increased delay, enabled by WABL
  [27] RESERVED16 — DSP0 ICACHE DATA RAM WABL - Write Assist Enable (active high)
  [26:25] RESERVED15 — DSP0 ICACHE DATA RAWLM
  [24] RESERVED14 — DSP0 ICACHE DATA RAWL
  [23:22] RESERVED13 — DSP0 ICACHE DATA EMAW
  [21] RESERVED12 — DSP0 ICACHE DATA EMAS
  [20:18] RESERVED11 — DSP0 ICACHE DATA EMA
  [17] RESERVED10 — Override for DSP0 ICACHE DATA RET1N override enable
  [16] RESERVED09 — DSP0 ICACHE DATA RET1N value
  [14:12] RESERVED07 — DSP0 ICACHE TAG WABLM - 00=No adjust 11=increased delay, enabled by WABL
  [11] RESERVED06 — DSP0 ICACHE TAG RAM WABL - Write Assist Enable (active high)
  [10:9] RESERVED05 — DSP0 ICACHE TAG RAWLM
  [8] RESERVED04 — DSP0 ICACHE TAG RAWL
  [7:6] RESERVED03 — DSP0 ICACHE TAG EMAW
  [5] RESERVED02 — DSP0 ICACHE TAG EMAS
  [4:2] RESERVED01 — DSP0 ICACHE TAG EMA
  [1] USBPHYUTMIRSTDIS — De-assert USB PHY UTMI reset override
  [0] USBPHYPORRSTDIS — De-assert USB PHY POR reset override
0x42C AUDADCPWRCTRL — Audio ADC Power Control
  [18] AUDADCKEEPOUTEN — Audio ADC reference keeper out en
  [17] AUDADCRFBUFSLWEN — Audio ADC reference buffer slew enable
  [16] AUDADCINBUFEN — Audio ADC Input Buffer Power Enable ( if the AUDADCPWRCTRLSWE bit is set )
  [15:14] AUDADCINBUFSEL — Audio ADC input buffer mux select
  [12] AUDADCVBATDIVEN — Audio ADC VBAT DIV Power Enable ( if the AUDADCPWRCTRLSWE bit is set )
  [10] VDDAUDADCRESETN — RESETN signal for Power Switched SAR and Digital Controller (when global power switch is off and if the AUDADCPWRCTRLSWE bit is set)
    values as ADCPWRCTRL.VDDADCRESETN
  [9] VDDAUDADCDIGISOLATE — ISOLATE signal for audio ADC Digital Contoller ( when AUDADCAPSEN is switched off and if the AUDADCPWRCTRLSWE bit is set)
    0=DIS (No Isolation); 1=EN (Isolate)
  [8] VDDAUDADCSARISOLATE — ISOLATE signal for Power Switched SAR ( when AUDADCBPSEN is switched off )
    0=DIS (No Isolation); 1=EN (Isolate)
  [5] AUDREFKEEPPEN — Reference Buffer Keeper Power Switch Enable
    values as ADCPWRCTRL.REFKEEPPEN
  [4] AUDREFBUFPEN — Reference Buffer Power Switch Enable
    values as ADCPWRCTRL.REFBUFPEN
  [3] AUDBGTPEN — Bandgap and Temperature Sensor Power Switch Enable
    values as ADCPWRCTRL.BGTLPPEN
  [2] AUDADCBPSEN — Enable the Analog, IO and SAR Digital logic Power Switch on when set to 1 if the AUDADCPWRCTRLSWE bit is set.
    0=DIS (AUDADC power switch software power disable.); 1=EN (AUDADC power switch software power enable.)
  [1] AUDADCAPSEN — Enable the Global audio ADC Power Switch on when set to 1 if the AUDADCPWRCTRLSWE bit is set.
    values as AUDADCBPSEN
  [0] AUDADCPWRCTRLSWE — Audio ADC Power Control Software Override Enable
    0=OVERRIDE_DIS (Audio ADC temperature sensor and bandgap Software Override Disable.); 1=OVERRIDE_EN (Audio ADC temperature sensor and bandgap Software Override Enable.)
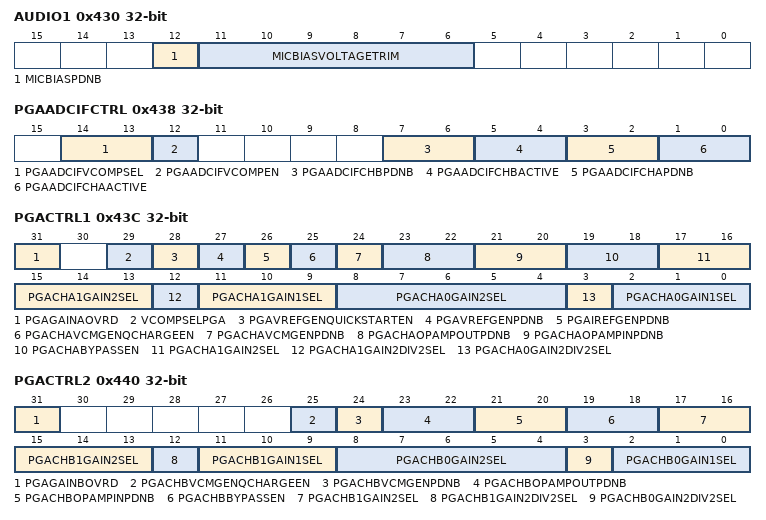
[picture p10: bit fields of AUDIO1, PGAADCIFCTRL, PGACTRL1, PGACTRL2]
0x430 AUDIO1 — Audio trims 1
  [12] MICBIASPDNB — Power down control for the block
  [11:6] MICBIASVOLTAGETRIM — Output voltage trim
0x438 PGAADCIFCTRL — PGA ADCIF control
  [14:13] PGAADCIFVCOMPSEL — Select for VCOMP output (0: A0, 1: A1, 2: B0, 3: B1)
  [12] PGAADCIFVCOMPEN — Enable for VCOMP output
  [7:6] PGAADCIFCHBPDNB — Power down for channels B0 and B1 (0 = powered down; 1 = standby)
  [5:4] PGAADCIFCHBACTIVE — PGAADCIF active signal for channels B0 and B1. Starts and stops 2 clocks after demultiplexed SOC signal.
  [3:2] PGAADCIFCHAPDNB — Power down for channels A0 and A1 (0 = powered down; 1 = standby)
  [1:0] PGAADCIFCHAACTIVE — PGAADCIF active signal for channels A0 and A1. Starts and stops 2 clocks after demultiplexed SOC signal.
0x43C PGACTRL1 — PGA control 1
  [31] PGAGAINAOVRD — Apply BYPASS and GAIN bits from this register (for channel A) instead of automatically via audio ADC. Note that audio ADC FIFO meta data will not reflect dB gain as used when configuring audio ADC.
  [29] VCOMPSELPGA — Select for VCOMP output (0: A0, 1: A1, 2: B0, 3: B1)
  [28] PGAVREFGENQUICKSTARTEN — VREFGEN quick start enable (pulsed during startup)
  [27] PGAVREFGENPDNB — VREFGEN power down (0: powered down, 1: powered up)
  [26] PGAIREFGENPDNB — IREFGEN power down (0: powered down, 1: powered up)
  [25] PGACHAVCMGENQCHARGEEN — Channel A VCMGEN quick charge enable (pulsed during channel powerup)
  [24] PGACHAVCMGENPDNB — Channel A VCMGEN power down (0: powered down, 1: powered up)
  [23:22] PGACHAOPAMPOUTPDNB — Channels A0 and A1 output stage opamp power down (0: powered down, 1: powered up)
  [21:20] PGACHAOPAMPINPDNB — Channels A0 and A1 input stage opamp power down (0: powered down, 1: powered up). Must be 1 when respective PGACHABYPASSEN = 0.
  [19:18] PGACHABYPASSEN — Bypass enable for Channels A0 and A1 (1: bypass, when gain LT 12 dB; 0: otherwise)
  [17:13] PGACHA1GAIN2SEL — Channel A1 PGA gain (0: 0dB, ..., 23: 11.5dB in 0.5 dB steps)
  [12] PGACHA1GAIN2DIV2SEL — Channel A1 PGA divide by two select (0: 0 dB, 1: -6dB), needed for fully differential inputs
  [11:9] PGACHA1GAIN1SEL — Channel A1 preamp gain (0: 12dB, ..., 7: 33dB in 3 dB steps)
  [8:4] PGACHA0GAIN2SEL — Channel A0 PGA gain (0: 0dB, ..., 23: 11.5dB in 0.5 dB steps)
  [3] PGACHA0GAIN2DIV2SEL — Channel A0 PGA divide by two select (0: 0 dB, 1: -6dB), needed for fully differential inputs
  [2:0] PGACHA0GAIN1SEL — Channel A0 preamp gain (0: 12dB, ..., 7: 33dB in 3 dB steps)
0x440 PGACTRL2 — PGA control 2
  [31] PGAGAINBOVRD — Apply BYPASS and GAIN bits from this register (for channel B) instead of automatically via audio ADC. Note that audio ADC FIFO meta data will not reflect dB gain as used when configuring audio ADC.
  [25] PGACHBVCMGENQCHARGEEN — Channel B VCMGEN quick charge enable (pulsed during channel powerup)
  [24] PGACHBVCMGENPDNB — Channel B VCMGEN power down (0: powered down, 1: powered up)
  [23:22] PGACHBOPAMPOUTPDNB — Channels B0 and B1 output stage opamp power down (0: powered down, 1: powered up)
  [21:20] PGACHBOPAMPINPDNB — Channels B0 and B1 input stage opamp power down (0: powered down, 1: powered up). Must be 1 when respective PGACHBBYPASSEN = 0.
  [19:18] PGACHBBYPASSEN — Bypass enable for Channels B0 and B1 (1: bypass, when gain LT 12 dB; 0: otherwise)
  [17:13] PGACHB1GAIN2SEL — Channel B1 PGA gain (0: 0dB, ..., 23: 11.5dB in 0.5 dB steps)
  [12] PGACHB1GAIN2DIV2SEL — Channel B1 PGA divide by two select (0: 0 dB, 1: -6dB), needed for fully differential inputs
  [11:9] PGACHB1GAIN1SEL — Channel B1 preamp gain (0: 12dB, ..., 7: 33dB in 3 dB steps)
  [8:4] PGACHB0GAIN2SEL — Channel B0 PGA gain (0: 0dB, ..., 23: 11.5dB in 0.5 dB steps)
  [3] PGACHB0GAIN2DIV2SEL — Channel B0 PGA divide by two select (0: 0 dB, 1: -6dB), needed for fully differential inputs
  [2:0] PGACHB0GAIN1SEL — Channel B0 preamp gain (0: 12dB, ..., 7: 33dB in 3 dB steps)
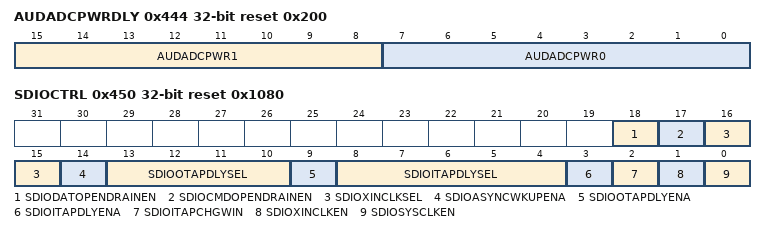
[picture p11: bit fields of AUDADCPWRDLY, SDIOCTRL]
0x444 AUDADCPWRDLY reset 0x200 — Audio ADC Power Up Delay Control
  [15:8] AUDADCPWR1 — ADC Reference Keeper enable delay in 16 ADC CLK increments for ADC_CLKSEL = 0x1, 8 ADC CLOCK increments for ADC_CLKSEL = 0x2.
  [7:0] AUDADCPWR0 — ADC Reference Buffer Power Enable delay in 64 ADC CLK increments for ADC_CLKSEL = 0x1, 32 ADC CLOCK increments for ADC_CLKSEL = 0x2.
0x450 SDIOCTRL reset 0x1080 — SDIO/eMMC Control
  [18] SDIODATOPENDRAINEN — SDIO DAT line configured as open-drian. 0: Push-pull mode, 1: Open-drain mode
  [17] SDIOCMDOPENDRAINEN — SDIO CMD line configured as open-drian. 0: Push-pull mode, 1: Open-drain mode
  [16:15] SDIOXINCLKSEL — Select clock source for SDIO xin_clk.
  [14] SDIOASYNCWKUPENA — SDIO asynchronous wakeup mode. 0: Synchronous wakeup mode, 1: Asynchronous wakeup mode
  [13:10] SDIOOTAPDLYSEL — Selects one of the 16 Taps on the sdcard_clk. This is effective only when otapdlyena is asserted.
  [9] SDIOOTAPDLYENA — Used to enable the selective Tap delay on the sdcard_clk so as to generate the delayed sdcard_clk. This is used to latch the CMD/DAT outputs to generate delay on them w.r.t CLK going out. This signal along with otapdlysel[3:0] selects the amount of delay to be inserted on the Clock line. This signal should not be asserted when operating in DS mode.
  [8:4] SDIOITAPDLYSEL — Selects one of the 32 Taps on the rxclk_in line. This is effective only when itapdlyena is asserted and Tuning is not enabled.
  [3] SDIOITAPDLYENA — Used to enable selective Tap delay line on the Looped back SD Clock (rxclk_in). This signal along with the itapdlysel[4:0] selects the the amount of delay to be inserted on the line. When Tuning is enabled (for SDR104 and optionally for SDR50), this signal is ignored and internalcontrols are used instead. This should not be asserted when operating in DS mode.
  [2] SDIOITAPCHGWIN — This is used to gate the output of the Tap Delay lines so as to avoid glithches being propagated into the Core. This signal should be asserted few clocks before the itapdlysel changes and should be asserted for few clocks after.
  [1] SDIOXINCLKEN — SDIO serial clock source enable.
  [0] SDIOSYSCLKEN — SDIO system clock enable.
0x454 PDMCTRL reset 0x1 — PDM Control
  [0] PDMGLOBALEN — PDM global enable to allow all PDMs to have synchronized interface clocks and FIFO sampling.
